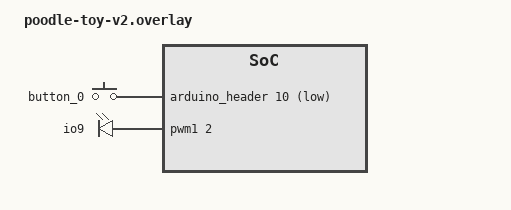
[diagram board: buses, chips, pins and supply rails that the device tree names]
/ {
	aliases {
		buzzer = &buzzer0;
		button0 = &button_0;
	};

	gpio_keys {
		compatible = "gpio-keys";
		button_0: button_0 {
			gpios = <&arduino_header 10 GPIO_ACTIVE_LOW>; // Header pin 4
		};
	};

	pwms {
		compatible = "pwm-leds";
		buzzer0: buzzer0 {
			pwms = <&pwm1 2 2500000 0>; // Header pin 6
			label = "io9";
		};
	};
};
